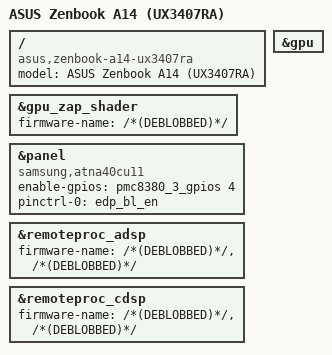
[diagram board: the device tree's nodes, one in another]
// SPDX-License-Identifier: BSD-3-Clause
/*
 * Copyright (c) 2025 Qualcomm Innovation Center, Inc. All rights reserved.
 * Copyright (c) 2025 Aleksandrs Vinarskis <alex.vinarskis@gmail.com>
 */

/dts-v1/;

#include "hamoa.dtsi"
#include "x1-asus-zenbook-a14.dtsi"

/ {
	model = "ASUS Zenbook A14 (UX3407RA)";
	compatible = "asus,zenbook-a14-ux3407ra", "qcom,x1e80100";
};

&gpu {
	status = "okay";
};

&gpu_zap_shader {
	firmware-name = "/*(DEBLOBBED)*/";
};

&panel {
	compatible = "samsung,atna40cu11", "samsung,atna33xc20";
	enable-gpios = <&pmc8380_3_gpios 4 GPIO_ACTIVE_HIGH>;

	pinctrl-0 = <&edp_bl_en>;
	pinctrl-names = "default";
};

&remoteproc_adsp {
	firmware-name = "/*(DEBLOBBED)*/",
			"/*(DEBLOBBED)*/";

	status = "okay";
};

&remoteproc_cdsp {
	firmware-name = "/*(DEBLOBBED)*/",
			"/*(DEBLOBBED)*/";

	status = "okay";
};
